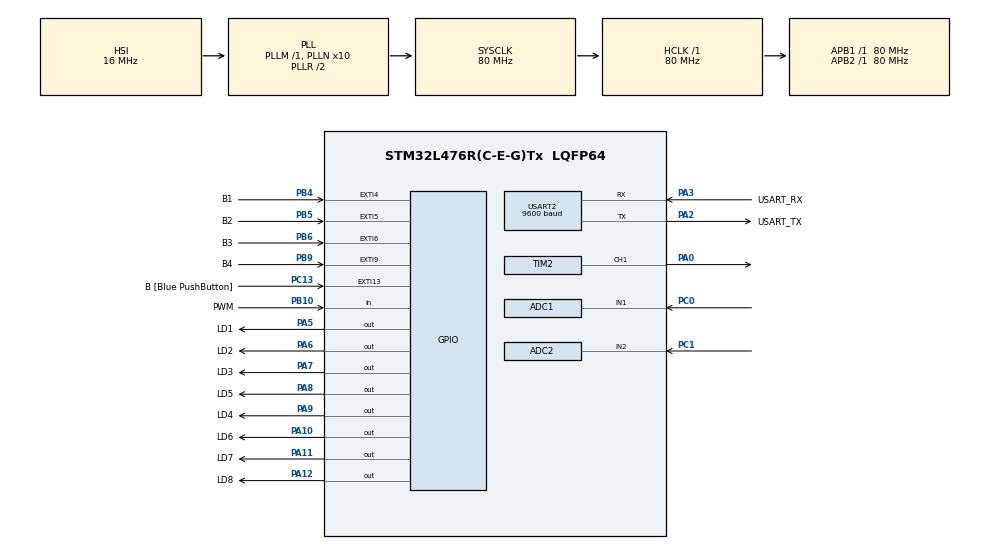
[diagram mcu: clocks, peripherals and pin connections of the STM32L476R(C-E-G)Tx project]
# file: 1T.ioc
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ADC1.Channel-0\#ChannelRegularConversion=ADC_CHANNEL_1
ADC1.ContinuousConvMode=ENABLE
ADC1.NbrOfConversionFlag=1
ADC1.OffsetNumber-0\#ChannelRegularConversion=ADC_OFFSET_NONE
ADC1.Rank-0\#ChannelRegularConversion=1
ADC1.SamplingTime-0\#ChannelRegularConversion=ADC_SAMPLETIME_2CYCLES_5
ADC1.master=1
ADC2.Channel-1\#ChannelRegularConversion=ADC_CHANNEL_2
ADC2.NbrOfConversionFlag=1
ADC2.OffsetNumber-1\#ChannelRegularConversion=ADC_OFFSET_NONE
ADC2.Rank-1\#ChannelRegularConversion=1
ADC2.SamplingTime-1\#ChannelRegularConversion=ADC_SAMPLETIME_2CYCLES_5
Mcu.Family=STM32L4
Mcu.Name=STM32L476R(C-E-G)Tx
Mcu.Package=LQFP64
NVIC.ADC1_2_IRQn=true\:1\:0\:true\:false\:true\:true\:true
NVIC.EXTI15_10_IRQn=true\:0\:0\:true\:false\:true\:true\:true
NVIC.EXTI4_IRQn=true\:0\:0\:false\:false\:true\:true\:true
NVIC.EXTI9_5_IRQn=true\:0\:0\:false\:false\:true\:true\:true
NVIC.PriorityGroup=NVIC_PRIORITYGROUP_4
NVIC.TIM2_IRQn=true\:0\:0\:false\:false\:true\:true\:true
NVIC.TIM3_IRQn=true\:0\:0\:false\:false\:true\:true\:true
NVIC.USART2_IRQn=true\:0\:0\:false\:false\:true\:true\:true
PA0.Signal=S_TIM2_CH1
PA10.GPIO_Label=LD6
PA10.Signal=GPIO_Output
PA11.GPIO_Label=LD7
PA11.Signal=GPIO_Output
PA12.GPIO_Label=LD8
PA12.Signal=GPIO_Output
PA13\ (JTMS-SWDIO).GPIO_Label=TMS
PA13\ (JTMS-SWDIO).Mode=Serial_Wire
PA13\ (JTMS-SWDIO).Signal=SYS_JTMS-SWDIO
PA14\ (JTCK-SWCLK).GPIO_Label=TCK
PA14\ (JTCK-SWCLK).Mode=Serial_Wire
PA14\ (JTCK-SWCLK).Signal=SYS_JTCK-SWCLK
PA2.GPIO_Label=USART_TX
PA2.GPIO_Mode=GPIO_MODE_AF_PP
PA2.GPIO_PuPd=GPIO_NOPULL
PA2.GPIO_Speed=GPIO_SPEED_FREQ_VERY_HIGH
PA2.Mode=Asynchronous
PA2.Signal=USART2_TX
PA3.GPIO_Label=USART_RX
PA3.GPIO_Mode=GPIO_MODE_AF_PP
PA3.GPIO_PuPd=GPIO_NOPULL
PA3.GPIO_Speed=GPIO_SPEED_FREQ_VERY_HIGH
PA3.Mode=Asynchronous
PA3.Signal=USART2_RX
PA5.GPIO_Label=LD1
PA5.Signal=GPIO_Output
PA6.GPIO_Label=LD2
PA6.Signal=GPIO_Output
PA7.GPIO_Label=LD3
PA7.Signal=GPIO_Output
PA8.GPIO_Label=LD5
PA8.Signal=GPIO_Output
PA9.GPIO_Label=LD4
PA9.Signal=GPIO_Output
PB10.GPIO_Label=PWM
PB10.Signal=GPIO_Input
PB3\ (JTDO-TRACESWO).GPIO_Label=SWO
PB3\ (JTDO-TRACESWO).Signal=SYS_JTDO-SWO
PB4\ (NJTRST).GPIO_Label=B1
PB4\ (NJTRST).GPIO_ModeDefaultEXTI=GPIO_MODE_IT_RISING_FALLING
PB4\ (NJTRST).Signal=GPXTI4
PB5.GPIO_Label=B2
PB5.GPIO_ModeDefaultEXTI=GPIO_MODE_IT_RISING_FALLING
PB5.Signal=GPXTI5
PB6.GPIO_Label=B3
PB6.GPIO_ModeDefaultEXTI=GPIO_MODE_IT_RISING_FALLING
PB6.Signal=GPXTI6
PB9.GPIO_Label=B4
PB9.GPIO_ModeDefaultEXTI=GPIO_MODE_IT_RISING_FALLING
PB9.Signal=GPXTI9
PC0.Signal=ADCx_IN1
PC1.Signal=ADCx_IN2
PC13.GPIO_Label=B [Blue PushButton]
PC13.GPIO_ModeDefaultEXTI=GPIO_MODE_IT_FALLING
PC13.GPIO_PuPd=GPIO_NOPULL
PC13.Signal=GPXTI13
PC14-OSC32_IN\ (PC14).Mode=LSE-External-Oscillator
PC14-OSC32_IN\ (PC14).Signal=RCC_OSC32_IN
PC15-OSC32_OUT\ (PC15).Mode=LSE-External-Oscillator
PC15-OSC32_OUT\ (PC15).Signal=RCC_OSC32_OUT
PH0-OSC_IN\ (PH0).Signal=RCC_OSC_IN
PH1-OSC_OUT\ (PH1).Signal=RCC_OSC_OUT
ProjectManager.HeapSize=0x200
ProjectManager.StackSize=0x400
ProjectManager.TargetToolchain=TrueSTUDIO
RCC.ADCFreq_Value=64000000
RCC.AHBFreq_Value=80000000
RCC.APB1Freq_Value=80000000
RCC.APB1TimFreq_Value=80000000
RCC.APB2Freq_Value=80000000
RCC.APB2TimFreq_Value=80000000
RCC.CortexFreq_Value=80000000
RCC.HCLKFreq_Value=80000000
RCC.HSE_VALUE=8000000
RCC.HSI_VALUE=16000000
RCC.MSI_VALUE=4000000
RCC.PLLN=10
RCC.PLLSourceVirtual=RCC_PLLSOURCE_HSI
RCC.PREFETCH_ENABLE=1
RCC.SYSCLKFreq_VALUE=80000000
RCC.SYSCLKSource=RCC_SYSCLKSOURCE_PLLCLK
RCC.USBFreq_Value=64000000
RCC.VCOOutputFreq_Value=160000000
SH.ADCx_IN1.0=ADC1_IN1,IN1-Single-Ended
SH.ADCx_IN2.0=ADC2_IN2,IN2-Single-Ended
SH.S_TIM2_CH1.0=TIM2_CH1,PWM Generation1 CH1
TIM2.Channel-PWM\ Generation1\ CH1=TIM_CHANNEL_1
TIM2.OCMode_PWM-PWM\ Generation1\ CH1=TIM_OCMODE_PWM1
TIM2.Period=1980
TIM2.Prescaler=655
TIM3.Period=4000
TIM3.Prescaler=39999
USART2.BaudRate=9600
USART2.VirtualMode-Asynchronous=VM_ASYNC
VP_TIM2_VS_ClockSourceINT.Mode=Internal
VP_TIM3_VS_ClockSourceINT.Mode=Internal
board=NUCLEO-L476RG

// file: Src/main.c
/* USER CODE BEGIN Header */
/**
  ******************************************************************************
  * @file           : main.c
  * @brief          : Main program body
  ******************************************************************************
  * @attention
  *
  * <h2><center>&copy; Copyright (c) 2020 STMicroelectronics.
  * All rights reserved.</center></h2>
  *
  * This software component is licensed by ST under BSD 3-Clause license,
  * the "License"; You may not use this file except in compliance with the
  * License. You may obtain a copy of the License at:
  *                        opensource.org/licenses/BSD-3-Clause
  *
  ******************************************************************************
  */
/* USER CODE END Header */

#include "main.h"
#include "adc.h"
#include "tim.h"
#include "usart.h"
#include "gpio.h"

/* USER CODE BEGIN Includes */
#include "variables.h"
/* USER CODE END Includes */

void SystemClock_Config(void);

int main(void)
{

  /* MCU Configuration--------------------------------------------------------*/

  /* Reset of all peripherals, Initializes the Flash interface and the Systick. */
  HAL_Init();

  /* Configure the system clock */
  SystemClock_Config();

  /* Initialize all configured peripherals */
  MX_GPIO_Init();
  MX_ADC1_Init();
  MX_TIM2_Init();
  MX_USART2_UART_Init();
  MX_ADC2_Init();
  MX_TIM3_Init();
  /* USER CODE BEGIN 2 */
  HAL_TIM_PWM_Start(&htim2, TIM_CHANNEL_1);			//inicializaciones.
  __HAL_TIM_SET_COMPARE(&htim2,TIM_CHANNEL_1, 1900);
  HAL_UART_Receive_IT(&huart2, &rData, 1);
  /* USER CODE END 2 */

  /* Infinite loop */
  while (1)
  {

  }
}

void SystemClock_Config(void)
{
  RCC_OscInitTypeDef RCC_OscInitStruct = {0};
  RCC_ClkInitTypeDef RCC_ClkInitStruct = {0};
  RCC_PeriphCLKInitTypeDef PeriphClkInit = {0};

  /** Initializes the CPU, AHB and APB busses clocks
  */
  RCC_OscInitStruct.OscillatorType = RCC_OSCILLATORTYPE_HSI;
  RCC_OscInitStruct.HSIState = RCC_HSI_ON;
  RCC_OscInitStruct.HSICalibrationValue = RCC_HSICALIBRATION_DEFAULT;
  RCC_OscInitStruct.PLL.PLLState = RCC_PLL_ON;
  RCC_OscInitStruct.PLL.PLLSource = RCC_PLLSOURCE_HSI;
  RCC_OscInitStruct.PLL.PLLM = 1;
  RCC_OscInitStruct.PLL.PLLN = 10;
  RCC_OscInitStruct.PLL.PLLP = RCC_PLLP_DIV7;
  RCC_OscInitStruct.PLL.PLLQ = RCC_PLLQ_DIV2;
  RCC_OscInitStruct.PLL.PLLR = RCC_PLLR_DIV2;
  if (HAL_RCC_OscConfig(&RCC_OscInitStruct) != HAL_OK)
  {
    Error_Handler();
  }
  /** Initializes the CPU, AHB and APB busses clocks
  */
  RCC_ClkInitStruct.ClockType = RCC_CLOCKTYPE_HCLK|RCC_CLOCKTYPE_SYSCLK
                              |RCC_CLOCKTYPE_PCLK1|RCC_CLOCKTYPE_PCLK2;
  RCC_ClkInitStruct.SYSCLKSource = RCC_SYSCLKSOURCE_PLLCLK;
  RCC_ClkInitStruct.AHBCLKDivider = RCC_SYSCLK_DIV1;
  RCC_ClkInitStruct.APB1CLKDivider = RCC_HCLK_DIV1;
  RCC_ClkInitStruct.APB2CLKDivider = RCC_HCLK_DIV1;

  if (HAL_RCC_ClockConfig(&RCC_ClkInitStruct, FLASH_LATENCY_4) != HAL_OK)
  {
    Error_Handler();
  }
  PeriphClkInit.PeriphClockSelection = RCC_PERIPHCLK_USART2|RCC_PERIPHCLK_ADC;
  PeriphClkInit.Usart2ClockSelection = RCC_USART2CLKSOURCE_PCLK1;
  PeriphClkInit.AdcClockSelection = RCC_ADCCLKSOURCE_PLLSAI1;
  PeriphClkInit.PLLSAI1.PLLSAI1Source = RCC_PLLSOURCE_HSI;
  PeriphClkInit.PLLSAI1.PLLSAI1M = 1;
  PeriphClkInit.PLLSAI1.PLLSAI1N = 8;
  PeriphClkInit.PLLSAI1.PLLSAI1P = RCC_PLLP_DIV7;
  PeriphClkInit.PLLSAI1.PLLSAI1Q = RCC_PLLQ_DIV2;
  PeriphClkInit.PLLSAI1.PLLSAI1R = RCC_PLLR_DIV2;
  PeriphClkInit.PLLSAI1.PLLSAI1ClockOut = RCC_PLLSAI1_ADC1CLK;
  if (HAL_RCCEx_PeriphCLKConfig(&PeriphClkInit) != HAL_OK)
  {
    Error_Handler();
  }
  /** Configure the main internal regulator output voltage
  */
  if (HAL_PWREx_ControlVoltageScaling(PWR_REGULATOR_VOLTAGE_SCALE1) != HAL_OK)
  {
    Error_Handler();
  }
}

void Error_Handler(void)
{
}

/************************ (C) COPYRIGHT STMicroelectronics *****END OF FILE****/
